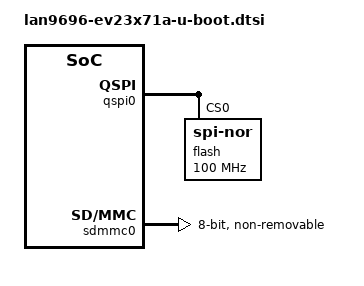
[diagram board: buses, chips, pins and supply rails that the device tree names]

#include "lan969x-u-boot.dtsi"
#include <dt-bindings/mscc/sparx5_data.h>

&switch {
	/delete-node/ ethernet-ports;

	ethernet-ports {
		#address-cells = <1>;
		#size-cells = <0>;

		port29: port@29 {
			reg = <29>;
			phy-handle = <&phy3>;
			phy-mode = "rgmii-rxid";
			phys = <IF_RGMII>;
		};
	};
};

&qspi0 {
	status = "okay";

	flash@0 {
		compatible = "jedec,spi-nor";
		reg = <0>;
		spi-max-frequency = <100000000>;
		spi-tx-bus-width = <1>;
		spi-rx-bus-width = <4>;
		m25p,fast-read;
	};
};

&sdmmc0 {
	pinctrl-0 = <&emmc_sd_pins>;
	pinctrl-names = "default";
	bus-width = <8>;
	mmc-ddr-1_8v;
	non-removable;
	no-sd;
	no-sdio;
	disable-wp;
	status = "okay";
};
